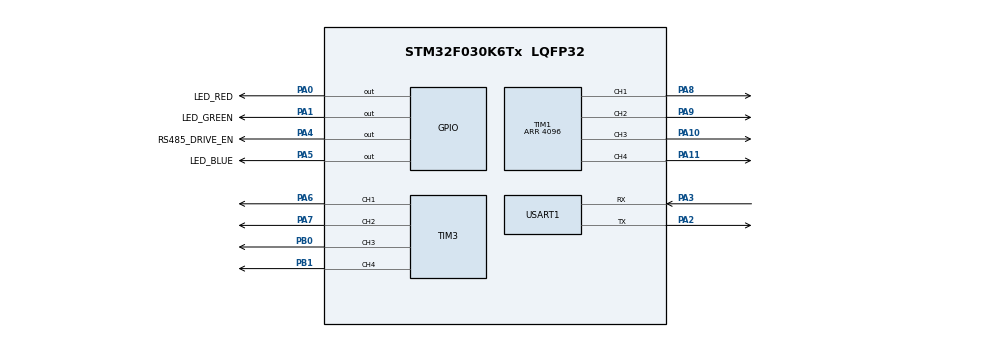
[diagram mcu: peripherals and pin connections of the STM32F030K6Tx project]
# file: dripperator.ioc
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Mcu.Family=STM32F0
Mcu.Name=STM32F030K6Tx
Mcu.Package=LQFP32
NVIC.USART1_IRQn=true\:0\:0\:false\:false\:true\:true\:true
PA0.GPIO_Label=LED_RED
PA0.GPIO_PuPd=GPIO_PULLUP
PA0.Signal=GPIO_Output
PA1.GPIO_Label=LED_GREEN
PA1.GPIO_PuPd=GPIO_PULLUP
PA1.Signal=GPIO_Output
PA10.Signal=S_TIM1_CH3
PA11.Signal=S_TIM1_CH4
PA13.Mode=Serial_Wire
PA13.Signal=SYS_SWDIO
PA14.Mode=Serial_Wire
PA14.Signal=SYS_SWCLK
PA2.Mode=Asynchronous
PA2.Signal=USART1_TX
PA3.Mode=Asynchronous
PA3.Signal=USART1_RX
PA4.GPIO_Label=RS485_DRIVE_EN
PA4.Signal=GPIO_Output
PA5.GPIO_Label=LED_BLUE
PA5.Signal=GPIO_Output
PA6.Signal=S_TIM3_CH1
PA7.Signal=S_TIM3_CH2
PA8.Signal=S_TIM1_CH1
PA9.Signal=S_TIM1_CH2
PB0.Signal=S_TIM3_CH3
PB1.Signal=S_TIM3_CH4
ProjectManager.HeapSize=0x200
ProjectManager.StackSize=0x400
ProjectManager.TargetToolchain=Other Toolchains (GPDSC)
SH.S_TIM1_CH1.0=TIM1_CH1,PWM Generation1 CH1
SH.S_TIM1_CH2.0=TIM1_CH2,PWM Generation2 CH2
SH.S_TIM1_CH3.0=TIM1_CH3,PWM Generation3 CH3
SH.S_TIM1_CH4.0=TIM1_CH4,PWM Generation4 CH4
SH.S_TIM3_CH1.0=TIM3_CH1,PWM Generation1 CH1
SH.S_TIM3_CH2.0=TIM3_CH2,PWM Generation2 CH2
SH.S_TIM3_CH3.0=TIM3_CH3,PWM Generation3 CH3
SH.S_TIM3_CH4.0=TIM3_CH4,PWM Generation4 CH4
TIM1.Channel-PWM\ Generation1\ CH1=TIM_CHANNEL_1
TIM1.Channel-PWM\ Generation2\ CH2=TIM_CHANNEL_2
TIM1.Channel-PWM\ Generation3\ CH3=TIM_CHANNEL_3
TIM1.Channel-PWM\ Generation4\ CH4=TIM_CHANNEL_4
TIM1.Period=4096
TIM3.Channel-PWM\ Generation1\ CH1=TIM_CHANNEL_1
TIM3.Channel-PWM\ Generation2\ CH2=TIM_CHANNEL_2
TIM3.Channel-PWM\ Generation3\ CH3=TIM_CHANNEL_3
TIM3.Channel-PWM\ Generation4\ CH4=TIM_CHANNEL_4
USART1.VirtualMode-Asynchronous=VM_ASYNC
VP_TIM1_VS_ClockSourceINT.Mode=Internal
VP_TIM3_VS_ClockSourceINT.Mode=Internal
board=custom

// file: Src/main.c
/* USER CODE BEGIN Header */
/**
  ******************************************************************************
  * @file           : main.c
  * @brief          : Main program body
  ******************************************************************************
  * @attention
  *
  * <h2><center>&copy; Copyright (c) 2023 STMicroelectronics.
  * All rights reserved.</center></h2>
  *
  * This software component is licensed by ST under BSD 3-Clause license,
  * the "License"; You may not use this file except in compliance with the
  * License. You may obtain a copy of the License at:
  *                        opensource.org/licenses/BSD-3-Clause
  *
  ******************************************************************************
  */
/* USER CODE END Header */
#include "main.h"
#include "tim.h"
#include "usart.h"
#include "gpio.h"

/* USER CODE BEGIN Includes */
#include "dripperator/dripperator.h"
/* USER CODE END Includes */

void SystemClock_Config(void);

int main(void)
{

  /* MCU Configuration--------------------------------------------------------*/

  /* Reset of all peripherals, Initializes the Flash interface and the Systick. */
  HAL_Init();

  /* Configure the system clock */
  SystemClock_Config();

  /* Initialize all configured peripherals */
  MX_GPIO_Init();
  MX_TIM1_Init();
  MX_TIM3_Init();
  MX_USART1_UART_Init();
  /* USER CODE BEGIN 2 */
  driperator_init();
  /* USER CODE END 2 */

  /* Infinite loop */
  /* USER CODE BEGIN WHILE */
  while (1)
  {
    driperator_update();
    /* USER CODE END WHILE */

  }
}

void SystemClock_Config(void)
{
  RCC_OscInitTypeDef RCC_OscInitStruct = {0};
  RCC_ClkInitTypeDef RCC_ClkInitStruct = {0};
  RCC_PeriphCLKInitTypeDef PeriphClkInit = {0};

  /** Initializes the RCC Oscillators according to the specified parameters
  * in the RCC_OscInitTypeDef structure.
  */
  RCC_OscInitStruct.OscillatorType = RCC_OSCILLATORTYPE_HSI;
  RCC_OscInitStruct.HSIState = RCC_HSI_ON;
  RCC_OscInitStruct.HSICalibrationValue = RCC_HSICALIBRATION_DEFAULT;
  RCC_OscInitStruct.PLL.PLLState = RCC_PLL_NONE;
  if (HAL_RCC_OscConfig(&RCC_OscInitStruct) != HAL_OK)
  {
    Error_Handler();
  }
  /** Initializes the CPU, AHB and APB buses clocks
  */
  RCC_ClkInitStruct.ClockType = RCC_CLOCKTYPE_HCLK|RCC_CLOCKTYPE_SYSCLK
                              |RCC_CLOCKTYPE_PCLK1;
  RCC_ClkInitStruct.SYSCLKSource = RCC_SYSCLKSOURCE_HSI;
  RCC_ClkInitStruct.AHBCLKDivider = RCC_SYSCLK_DIV1;
  RCC_ClkInitStruct.APB1CLKDivider = RCC_HCLK_DIV1;

  if (HAL_RCC_ClockConfig(&RCC_ClkInitStruct, FLASH_LATENCY_0) != HAL_OK)
  {
    Error_Handler();
  }
  PeriphClkInit.PeriphClockSelection = RCC_PERIPHCLK_USART1;
  PeriphClkInit.Usart1ClockSelection = RCC_USART1CLKSOURCE_PCLK1;
  if (HAL_RCCEx_PeriphCLKConfig(&PeriphClkInit) != HAL_OK)
  {
    Error_Handler();
  }
}

void Error_Handler(void)
{
  __disable_irq();
  while (1)
  {
  }
}

/************************ (C) COPYRIGHT STMicroelectronics *****END OF FILE****/
